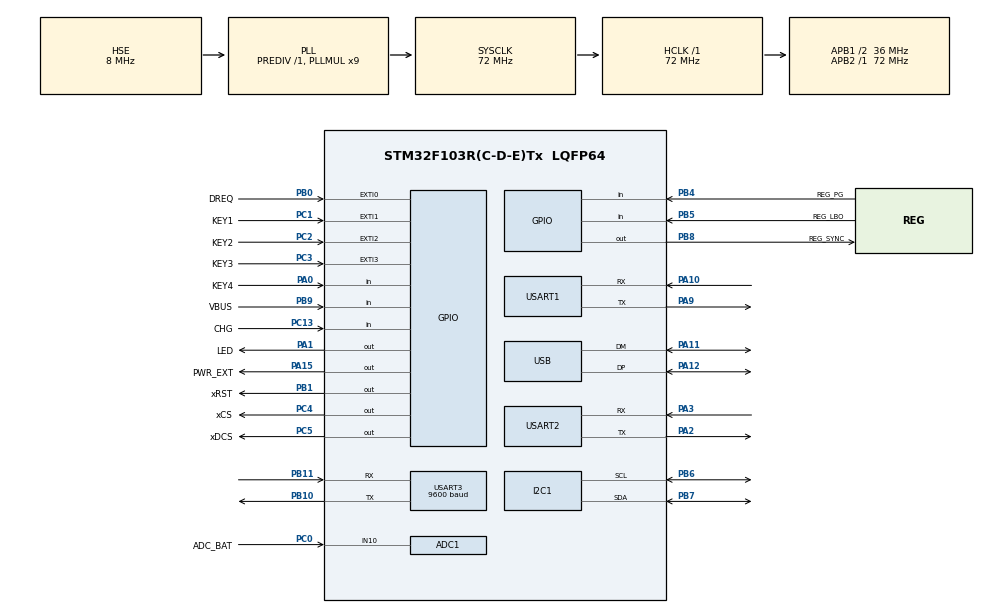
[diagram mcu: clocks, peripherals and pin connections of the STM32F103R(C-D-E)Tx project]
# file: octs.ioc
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ADC1.Channel-0\#ChannelRegularConversion=ADC_CHANNEL_10
ADC1.NbrOfConversionFlag=1
ADC1.Rank-0\#ChannelRegularConversion=1
ADC1.SamplingTime-0\#ChannelRegularConversion=ADC_SAMPLETIME_1CYCLE_5
ADC1.master=1
FREERTOS.Tasks01=defaultTask,-2,128,StartDefaultTask,Default,NULL,Dynamic,NULL,NULL
FREERTOS.configCHECK_FOR_STACK_OVERFLOW=2
FREERTOS.configTICK_RATE_HZ=100
FREERTOS.configTOTAL_HEAP_SIZE=10240
FREERTOS.configUSE_TIMERS=1
FREERTOS.configUSE_TRACE_FACILITY=1
Mcu.Family=STM32F1
Mcu.Name=STM32F103R(C-D-E)Tx
Mcu.Package=LQFP64
NVIC.EXTI0_IRQn=true\:5\:0\:true\:false\:true\:true\:true\:true
NVIC.EXTI1_IRQn=true\:10\:0\:true\:false\:true\:true\:true\:true
NVIC.EXTI2_IRQn=true\:10\:0\:true\:false\:true\:true\:true\:true
NVIC.EXTI3_IRQn=true\:10\:0\:true\:false\:true\:true\:true\:true
NVIC.PriorityGroup=NVIC_PRIORITYGROUP_4
NVIC.TIM1_UP_IRQn=true\:0\:0\:false\:false\:true\:false\:true\:true
NVIC.TimeBase=TIM1_UP_IRQn
NVIC.TimeBaseIP=TIM1
NVIC.USB_LP_CAN1_RX0_IRQn=true\:5\:0\:false\:false\:true\:true\:false\:true
PA0-WKUP.GPIO_Label=KEY4
PA0-WKUP.GPIO_PuPd=GPIO_PULLUP
PA0-WKUP.Signal=GPIO_Input
PA1.GPIO_Label=LED
PA1.Signal=GPIO_Output
PA10.Mode=Asynchronous
PA10.Signal=USART1_RX
PA11.Mode=Device
PA11.Signal=USB_DM
PA12.Mode=Device
PA12.Signal=USB_DP
PA13.GPIO_Label=SWDIO
PA13.Mode=Serial_Wire
PA13.Signal=SYS_JTMS-SWDIO
PA14.GPIO_Label=SWCLK
PA14.Mode=Serial_Wire
PA14.Signal=SYS_JTCK-SWCLK
PA15.GPIO_Label=PWR_EXT
PA15.Signal=GPIO_Output
PA2.Mode=Asynchronous
PA2.Signal=USART2_TX
PA3.Mode=Asynchronous
PA3.Signal=USART2_RX
PA4.GPIO_Label=VDAC
PA4.Signal=COMP_DAC1_group
PA9.Mode=Asynchronous
PA9.Signal=USART1_TX
PB0.GPIO_Label=DREQ
PB0.Signal=GPXTI0
PB1.GPIO_Label=xRST
PB1.Signal=GPIO_Output
PB10.Mode=Asynchronous
PB10.Signal=USART3_TX
PB11.Mode=Asynchronous
PB11.Signal=USART3_RX
PB4.GPIO_Label=REG_PG
PB4.GPIO_PuPd=GPIO_PULLUP
PB4.Signal=GPIO_Input
PB5.GPIO_Label=REG_LBO
PB5.GPIO_PuPd=GPIO_PULLUP
PB5.Signal=GPIO_Input
PB6.Mode=I2C
PB6.Signal=I2C1_SCL
PB7.Mode=I2C
PB7.Signal=I2C1_SDA
PB8.GPIO_Label=REG_SYNC
PB8.Signal=GPIO_Output
PB9.GPIO_Label=VBUS
PB9.GPIO_PuPd=GPIO_NOPULL
PB9.Signal=GPIO_Input
PC0.GPIO_Label=ADC_BAT
PC0.Signal=ADCx_IN10
PC1.GPIO_Label=KEY1
PC1.GPIO_ModeDefaultEXTI=GPIO_MODE_IT_FALLING
PC1.GPIO_PuPd=GPIO_PULLUP
PC1.Signal=GPXTI1
PC13-TAMPER-RTC.GPIO_Label=CHG
PC13-TAMPER-RTC.GPIO_PuPd=GPIO_PULLUP
PC13-TAMPER-RTC.Signal=GPIO_Input
PC14-OSC32_IN.Mode=LSE-External-Oscillator
PC14-OSC32_IN.Signal=RCC_OSC32_IN
PC15-OSC32_OUT.Mode=LSE-External-Oscillator
PC15-OSC32_OUT.Signal=RCC_OSC32_OUT
PC2.GPIO_Label=KEY2
PC2.GPIO_ModeDefaultEXTI=GPIO_MODE_IT_FALLING
PC2.GPIO_PuPd=GPIO_PULLUP
PC2.Signal=GPXTI2
PC3.GPIO_Label=KEY3
PC3.GPIO_ModeDefaultEXTI=GPIO_MODE_IT_FALLING
PC3.GPIO_PuPd=GPIO_PULLUP
PC3.Signal=GPXTI3
PC4.GPIO_Label=xCS
PC4.PinState=GPIO_PIN_SET
PC4.Signal=GPIO_Output
PC5.GPIO_Label=xDCS
PC5.PinState=GPIO_PIN_SET
PC5.Signal=GPIO_Output
PD0-OSC_IN.Mode=HSE-External-Oscillator
PD0-OSC_IN.Signal=RCC_OSC_IN
PD1-OSC_OUT.Mode=HSE-External-Oscillator
PD1-OSC_OUT.Signal=RCC_OSC_OUT
ProjectManager.HeapSize=0x400
ProjectManager.StackSize=0x800
ProjectManager.TargetToolchain=MDK-ARM V5.27
RCC.ADCPresc=RCC_ADCPCLK2_DIV6
RCC.AHBFreq_Value=72000000
RCC.APB1CLKDivider=RCC_HCLK_DIV2
RCC.APB1Freq_Value=36000000
RCC.APB1TimFreq_Value=72000000
RCC.APB2Freq_Value=72000000
RCC.APB2TimFreq_Value=72000000
RCC.HCLKFreq_Value=72000000
RCC.PLLMUL=RCC_PLL_MUL9
RCC.PLLSourceVirtual=RCC_PLLSOURCE_HSE
RCC.SYSCLKFreq_VALUE=72000000
RCC.SYSCLKSource=RCC_SYSCLKSOURCE_PLLCLK
RCC.USBFreq_Value=48000000
RCC.USBPrescaler=RCC_USBCLKSOURCE_PLL_DIV1_5
SH.ADCx_IN10.0=ADC1_IN10,IN10
SH.COMP_DAC1_group.0=DAC_OUT1
USART1.VirtualMode=VM_ASYNC
USART2.VirtualMode=VM_ASYNC
USART3.BaudRate=9600
USART3.VirtualMode=VM_ASYNC
USB_DEVICE.CLASS_NAME_FS=CDC
USB_DEVICE.VirtualMode=Cdc
USB_DEVICE.VirtualModeFS=Cdc_FS
VP_CRC_VS_CRC.Mode=CRC_Activate
VP_FREERTOS_VS_CMSIS_V1.Mode=CMSIS_V1
VP_SYS_VS_tim1.Mode=TIM1
VP_USB_DEVICE_VS_USB_DEVICE_CDC_FS.Mode=CDC_FS
board=MP3P

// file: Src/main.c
/* USER CODE BEGIN Header */
/**
  ******************************************************************************
  * @file           : main.c
  * @brief          : Main program body
  ******************************************************************************
  * @attention
  *
  * <h2><center>&copy; Copyright (c) 2021 STMicroelectronics.
  * All rights reserved.</center></h2>
  *
  * This software component is licensed by ST under Ultimate Liberty license
  * SLA0044, the "License"; You may not use this file except in compliance with
  * the License. You may obtain a copy of the License at:
  *                             www.st.com/SLA0044
  *
  ******************************************************************************
  */
/* USER CODE END Header */
#include "main.h"
#include "cmsis_os.h"
#include "adc.h"
#include "crc.h"
#include "i2c.h"
#include "usart.h"
#include "usb_device.h"
#include "gpio.h"

/* USER CODE BEGIN Includes */
#include <stdio.h>
#include "debug.h"
#include "lwgps/lwgps.h"
/* USER CODE END Includes */

void SystemClock_Config(void);
void MX_FREERTOS_Init(void);

int main(void)
{

  /* MCU Configuration--------------------------------------------------------*/

  /* Reset of all peripherals, Initializes the Flash interface and the Systick. */
  HAL_Init();

  /* Configure the system clock */
  SystemClock_Config();

  /* Initialize all configured peripherals */
  MX_GPIO_Init();
  MX_USART2_UART_Init();
  MX_ADC1_Init();
  MX_I2C1_Init();
  MX_CRC_Init();
  MX_USART1_UART_Init();
  MX_USART3_UART_Init();
  /* USER CODE BEGIN 2 */
	debug_print("OCTS here ...\r\n");
  /* USER CODE END 2 */

  /* Call init function for freertos objects (in freertos.c) */
  MX_FREERTOS_Init();
  /* Start scheduler */
  osKernelStart();

  /* We should never get here as control is now taken by the scheduler */
  /* Infinite loop */
  while (1)
  {

  }
}

void SystemClock_Config(void)
{
  RCC_OscInitTypeDef RCC_OscInitStruct = {0};
  RCC_ClkInitTypeDef RCC_ClkInitStruct = {0};
  RCC_PeriphCLKInitTypeDef PeriphClkInit = {0};

  /** Initializes the RCC Oscillators according to the specified parameters
  * in the RCC_OscInitTypeDef structure.
  */
  RCC_OscInitStruct.OscillatorType = RCC_OSCILLATORTYPE_HSE;
  RCC_OscInitStruct.HSEState = RCC_HSE_ON;
  RCC_OscInitStruct.HSEPredivValue = RCC_HSE_PREDIV_DIV1;
  RCC_OscInitStruct.HSIState = RCC_HSI_ON;
  RCC_OscInitStruct.PLL.PLLState = RCC_PLL_ON;
  RCC_OscInitStruct.PLL.PLLSource = RCC_PLLSOURCE_HSE;
  RCC_OscInitStruct.PLL.PLLMUL = RCC_PLL_MUL9;
  if (HAL_RCC_OscConfig(&RCC_OscInitStruct) != HAL_OK)
  {
    Error_Handler();
  }
  /** Initializes the CPU, AHB and APB buses clocks
  */
  RCC_ClkInitStruct.ClockType = RCC_CLOCKTYPE_HCLK|RCC_CLOCKTYPE_SYSCLK
                              |RCC_CLOCKTYPE_PCLK1|RCC_CLOCKTYPE_PCLK2;
  RCC_ClkInitStruct.SYSCLKSource = RCC_SYSCLKSOURCE_PLLCLK;
  RCC_ClkInitStruct.AHBCLKDivider = RCC_SYSCLK_DIV1;
  RCC_ClkInitStruct.APB1CLKDivider = RCC_HCLK_DIV2;
  RCC_ClkInitStruct.APB2CLKDivider = RCC_HCLK_DIV1;

  if (HAL_RCC_ClockConfig(&RCC_ClkInitStruct, FLASH_LATENCY_2) != HAL_OK)
  {
    Error_Handler();
  }
  PeriphClkInit.PeriphClockSelection = RCC_PERIPHCLK_ADC|RCC_PERIPHCLK_USB;
  PeriphClkInit.AdcClockSelection = RCC_ADCPCLK2_DIV6;
  PeriphClkInit.UsbClockSelection = RCC_USBCLKSOURCE_PLL_DIV1_5;
  if (HAL_RCCEx_PeriphCLKConfig(&PeriphClkInit) != HAL_OK)
  {
    Error_Handler();
  }
}

 /**
  * @brief  Period elapsed callback in non blocking mode
  * @note   This function is called  when TIM1 interrupt took place, inside
  * HAL_TIM_IRQHandler(). It makes a direct call to HAL_IncTick() to increment
  * a global variable "uwTick" used as application time base.
  * @param  htim : TIM handle
  * @retval None
  */
void HAL_TIM_PeriodElapsedCallback(TIM_HandleTypeDef *htim)
{
  if (htim->Instance == TIM1) {
    HAL_IncTick();
  }
}

void Error_Handler(void)
{
  /* USER CODE BEGIN Error_Handler_Debug */
  /* User can add his own implementation to report the HAL error return state */
  __disable_irq();
  debug_print("error-handler:\r\n");
  /* USER CODE END Error_Handler_Debug */
}

/************************ (C) COPYRIGHT STMicroelectronics *****END OF FILE****/

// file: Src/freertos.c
/* USER CODE BEGIN Header */
/**
  ******************************************************************************
  * File Name          : freertos.c
  * Description        : Code for freertos applications
  ******************************************************************************
  * @attention
  *
  * <h2><center>&copy; Copyright (c) 2021 STMicroelectronics.
  * All rights reserved.</center></h2>
  *
  * This software component is licensed by ST under Ultimate Liberty license
  * SLA0044, the "License"; You may not use this file except in compliance with
  * the License. You may obtain a copy of the License at:
  *                             www.st.com/SLA0044
  *
  ******************************************************************************
  */
/* USER CODE END Header */

#include "FreeRTOS.h"
#include "task.h"
#include "main.h"
#include "cmsis_os.h"

osThreadId defaultTaskHandle;

void StartDefaultTask(void const * argument);

extern void MX_USB_DEVICE_Init(void);
void MX_FREERTOS_Init(void); /* (MISRA C 2004 rule 8.1) */

/* GetIdleTaskMemory prototype (linked to static allocation support) */
void vApplicationGetIdleTaskMemory( StaticTask_t **ppxIdleTaskTCBBuffer, StackType_t **ppxIdleTaskStackBuffer, uint32_t *pulIdleTaskStackSize );

/* GetTimerTaskMemory prototype (linked to static allocation support) */
void vApplicationGetTimerTaskMemory( StaticTask_t **ppxTimerTaskTCBBuffer, StackType_t **ppxTimerTaskStackBuffer, uint32_t *pulTimerTaskStackSize );

/* Hook prototypes */
void vApplicationStackOverflowHook(xTaskHandle xTask, signed char *pcTaskName);

/* USER CODE BEGIN 4 */
__weak void vApplicationStackOverflowHook(xTaskHandle xTask, signed char *pcTaskName)
{
   /* Run time stack overflow checking is performed if
   configCHECK_FOR_STACK_OVERFLOW is defined to 1 or 2. This hook function is
   called if a stack overflow is detected. */
}
/* USER CODE END 4 */

/* USER CODE BEGIN GET_IDLE_TASK_MEMORY */
static StaticTask_t xIdleTaskTCBBuffer;
static StackType_t xIdleStack[configMINIMAL_STACK_SIZE];

void vApplicationGetIdleTaskMemory( StaticTask_t **ppxIdleTaskTCBBuffer, StackType_t **ppxIdleTaskStackBuffer, uint32_t *pulIdleTaskStackSize )
{
  *ppxIdleTaskTCBBuffer = &xIdleTaskTCBBuffer;
  *ppxIdleTaskStackBuffer = &xIdleStack[0];
  *pulIdleTaskStackSize = configMINIMAL_STACK_SIZE;
  /* place for user code */
}
/* USER CODE END GET_IDLE_TASK_MEMORY */

/* USER CODE BEGIN GET_TIMER_TASK_MEMORY */
static StaticTask_t xTimerTaskTCBBuffer;
static StackType_t xTimerStack[configTIMER_TASK_STACK_DEPTH];

void vApplicationGetTimerTaskMemory( StaticTask_t **ppxTimerTaskTCBBuffer, StackType_t **ppxTimerTaskStackBuffer, uint32_t *pulTimerTaskStackSize )
{
  *ppxTimerTaskTCBBuffer = &xTimerTaskTCBBuffer;
  *ppxTimerTaskStackBuffer = &xTimerStack[0];
  *pulTimerTaskStackSize = configTIMER_TASK_STACK_DEPTH;
  /* place for user code */
}
/* USER CODE END GET_TIMER_TASK_MEMORY */

void MX_FREERTOS_Init(void) {

  /* Create the thread(s) */
  /* definition and creation of defaultTask */
  osThreadDef(defaultTask, StartDefaultTask, osPriorityLow, 0, 128);
  defaultTaskHandle = osThreadCreate(osThread(defaultTask), NULL);

}

void StartDefaultTask(void const * argument)
{
  /* init code for USB_DEVICE */
  MX_USB_DEVICE_Init();
  for(;;)
  {
    osDelay(1);
  }
}

/************************ (C) COPYRIGHT STMicroelectronics *****END OF FILE****/
